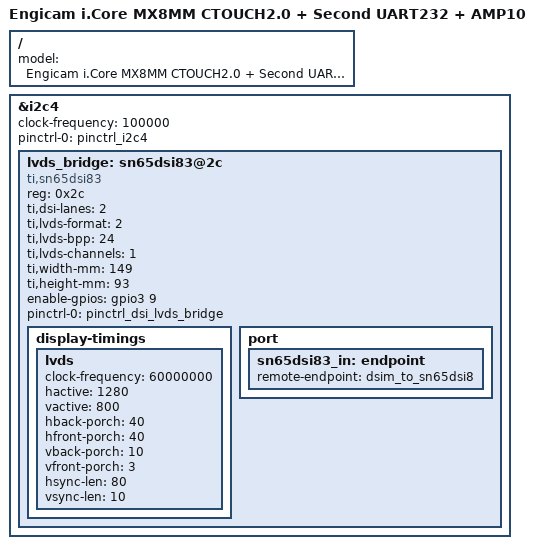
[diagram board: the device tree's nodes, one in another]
// SPDX-License-Identifier: (GPL-2.0+ OR MIT)
/*
 * Copyright 2021 Engicam srl
 * Copyright 2019 NXP
 */

#include "imx8mm-icore-ctouch2-rs232.dts"

/ {
	model = "Engicam i.Core MX8MM CTOUCH2.0 + Second UART232 + AMP10";
};

&i2c4 {
  clock-frequency = <100000>;
  pinctrl-names = "default";
  pinctrl-0 = <&pinctrl_i2c4>;
  status = "okay";

  lvds_bridge: sn65dsi83@2c {
    compatible = "ti,sn65dsi83";
    reg = <0x2c>;
    ti,dsi-lanes = <2>;
    ti,lvds-format = <2>;
    ti,lvds-bpp = <24>;
    ti,lvds-channels = <1>;
    ti,width-mm = <149>;
    ti,height-mm = <93>;
    enable-gpios = <&gpio3 9  GPIO_ACTIVE_HIGH>;
    pinctrl-names = "default";
    pinctrl-0 = <&pinctrl_dsi_lvds_bridge>;
    status = "okay";

    display-timings {
      lvds {
        clock-frequency = <60000000>;
        hactive = <1280>;
        vactive = <800>;
        hback-porch = <40>;
        hfront-porch = <40>;
        vback-porch = <10>;
        vfront-porch = <3>;
        hsync-len = <80>;
        vsync-len = <10>;
      };
    };

    port {
      sn65dsi83_in: endpoint {
        remote-endpoint = <&dsim_to_sn65dsi8>;
      };
    };
  };
};
